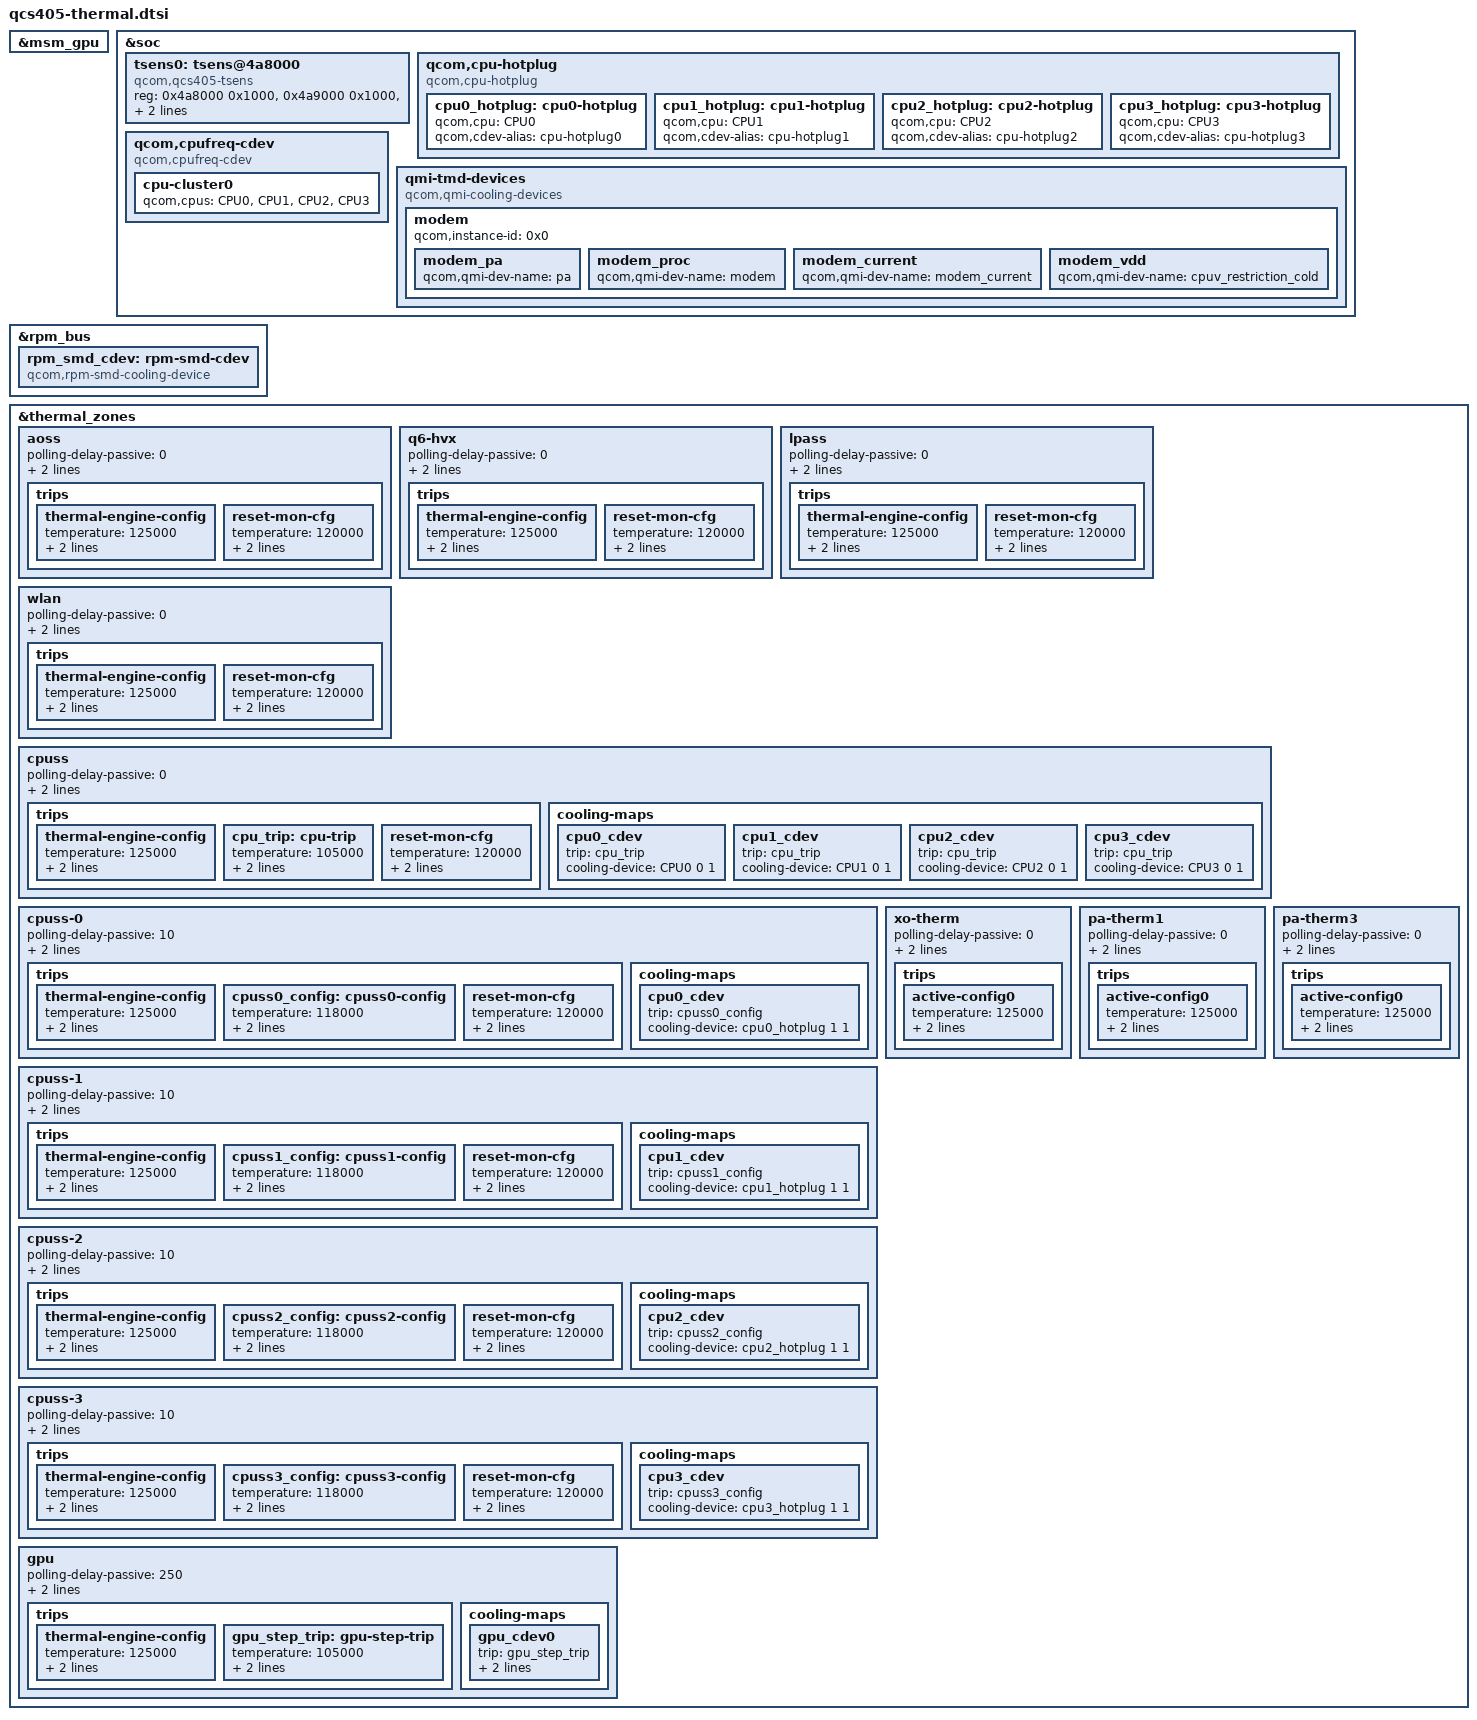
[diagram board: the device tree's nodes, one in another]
#include <dt-bindings/thermal/thermal_qti.h>

&msm_gpu {
    #cooling-cells = <2>;
};

&soc {
	tsens0: tsens@4a8000 {
		compatible = "qcom,qcs405-tsens";
		reg = <0x4a8000 0x1000>,
			<0x4a9000 0x1000>,
			<0xa4000  0x1000>;
		reg-names = "tsens_srot_physical",
			"tsens_tm_physical",
			"tsens_eeprom_physical";
		interrupts = <GIC_SPI 184 IRQ_TYPE_LEVEL_HIGH>;
		interrupt-names = "tsens-upper-lower";
		#thermal-sensor-cells = <1>;
	};

	qcom,cpu-hotplug {
		compatible = "qcom,cpu-hotplug";

		cpu0_hotplug: cpu0-hotplug {
			qcom,cpu = <&CPU0>;
			qcom,cdev-alias = "cpu-hotplug0";
			#cooling-cells = <2>;
		};

		cpu1_hotplug: cpu1-hotplug {
			qcom,cpu = <&CPU1>;
			qcom,cdev-alias = "cpu-hotplug1";
			#cooling-cells = <2>;
		};

		cpu2_hotplug: cpu2-hotplug {
			qcom,cpu = <&CPU2>;
			qcom,cdev-alias = "cpu-hotplug2";
			#cooling-cells = <2>;
		};

		cpu3_hotplug: cpu3-hotplug {
			qcom,cpu = <&CPU3>;
			qcom,cdev-alias = "cpu-hotplug3";
			#cooling-cells = <2>;
		};
	};

	qcom,cpufreq-cdev {
		compatible = "qcom,cpufreq-cdev";
		cpu-cluster0 {
			qcom,cpus = <&CPU0 &CPU1 &CPU2 &CPU3>;
		};
	};

	qmi-tmd-devices {
		compatible = "qcom,qmi-cooling-devices";

		modem {
			qcom,instance-id = <0x0>;

			modem_pa: modem_pa {
				qcom,qmi-dev-name = "pa";
				#cooling-cells = <2>;
			};

			modem_proc: modem_proc {
				qcom,qmi-dev-name = "modem";
				#cooling-cells = <2>;
			};

			modem_current: modem_current {
				qcom,qmi-dev-name = "modem_current";
				#cooling-cells = <2>;
			};

			modem_vdd: modem_vdd {
				qcom,qmi-dev-name = "cpuv_restriction_cold";
				#cooling-cells = <2>;
			};
		};
	};
};

&rpm_bus {
	rpm_smd_cdev: rpm-smd-cdev {
		compatible = "qcom,rpm-smd-cooling-device";
		#cooling-cells = <2>;
	};
};

&thermal_zones {
	aoss {
		polling-delay-passive = <0>;
		polling-delay = <0>;
		thermal-sensors = <&tsens0 0>;
		trips {
			thermal-engine-config {
				temperature = <125000>;
				hysteresis = <1000>;
				type = "passive";
			};

			reset-mon-cfg {
				temperature = <120000>;
				hysteresis = <5000>;
				type = "passive";
			};
		};
	};

	q6-hvx {
		polling-delay-passive = <0>;
		polling-delay = <0>;
		thermal-sensors = <&tsens0 1>;
		trips {
			thermal-engine-config {
				temperature = <125000>;
				hysteresis = <1000>;
				type = "passive";
			};

			reset-mon-cfg {
				temperature = <120000>;
				hysteresis = <5000>;
				type = "passive";
			};
		};
	};

	lpass {
		polling-delay-passive = <0>;
		polling-delay = <0>;
		thermal-sensors = <&tsens0 2>;
		trips {
			thermal-engine-config {
				temperature = <125000>;
				hysteresis = <1000>;
				type = "passive";
			};

			reset-mon-cfg {
				temperature = <120000>;
				hysteresis = <5000>;
				type = "passive";
			};
		};
	};

	wlan {
		polling-delay-passive = <0>;
		polling-delay = <0>;
		thermal-sensors = <&tsens0 3>;
		trips {
			thermal-engine-config {
				temperature = <125000>;
				hysteresis = <1000>;
				type = "passive";
			};

			reset-mon-cfg {
				temperature = <120000>;
				hysteresis = <5000>;
				type = "passive";
			};
		};
	};

	cpuss {
		polling-delay-passive = <0>;
		polling-delay = <0>;
		thermal-sensors = <&tsens0 4>;
		trips {
			thermal-engine-config {
				temperature = <125000>;
				hysteresis = <1000>;
				type = "passive";
			};

			cpu_trip:cpu-trip {
				temperature = <105000>;
				hysteresis = <0>;
				type = "passive";
			};

			reset-mon-cfg {
				temperature = <120000>;
				hysteresis = <5000>;
				type = "passive";
			};
		};

		cooling-maps {
			cpu0_cdev {
				trip = <&cpu_trip>;
				cooling-device = <&CPU0 0 1>;
			};

			cpu1_cdev {
				trip = <&cpu_trip>;
				cooling-device = <&CPU1 0 1>;
			};

			cpu2_cdev {
				trip = <&cpu_trip>;
				cooling-device = <&CPU2 0 1>;
			};

			cpu3_cdev {
				trip = <&cpu_trip>;
				cooling-device = <&CPU3 0 1>;
			};
		};
	};

	cpuss-0 {
		polling-delay-passive = <10>;
		polling-delay = <0>;
		thermal-sensors = <&tsens0 5>;
		trips {
			thermal-engine-config {
				temperature = <125000>;
				hysteresis = <1000>;
				type = "passive";
			};

			cpuss0_config: cpuss0-config {
				temperature = <118000>;
				hysteresis = <10000>;
				type = "passive";
			};

			reset-mon-cfg {
				temperature = <120000>;
				hysteresis = <5000>;
				type = "passive";
			};
		};

		cooling-maps {
			cpu0_cdev {
				trip = <&cpuss0_config>;
				cooling-device = <&cpu0_hotplug 1 1>;
			};
		};
	};

	cpuss-1 {
		polling-delay-passive = <10>;
		polling-delay = <0>;
		thermal-sensors = <&tsens0 6>;
		trips {
			thermal-engine-config {
				temperature = <125000>;
				hysteresis = <1000>;
				type = "passive";
			};

			cpuss1_config: cpuss1-config {
				temperature = <118000>;
				hysteresis = <10000>;
				type = "passive";
			};

			reset-mon-cfg {
				temperature = <120000>;
				hysteresis = <5000>;
				type = "passive";
			};
		};

		cooling-maps {
			cpu1_cdev {
				trip = <&cpuss1_config>;
				cooling-device = <&cpu1_hotplug 1 1>;
			};
		};
	};

	cpuss-2 {
		polling-delay-passive = <10>;
		polling-delay = <0>;
		thermal-sensors = <&tsens0 7>;
		trips {
			thermal-engine-config {
				temperature = <125000>;
				hysteresis = <1000>;
				type = "passive";
			};

			cpuss2_config: cpuss2-config {
				temperature = <118000>;
				hysteresis = <10000>;
				type = "passive";
			};

			reset-mon-cfg {
				temperature = <120000>;
				hysteresis = <5000>;
				type = "passive";
			};
		};

		cooling-maps {
			cpu2_cdev {
				trip = <&cpuss2_config>;
				cooling-device = <&cpu2_hotplug 1 1>;
			};
		};
	};

	cpuss-3 {
		polling-delay-passive = <10>;
		polling-delay = <0>;
		thermal-sensors = <&tsens0 8>;
		trips {
			thermal-engine-config {
				temperature = <125000>;
				hysteresis = <1000>;
				type = "passive";
			};

			cpuss3_config: cpuss3-config {
				temperature = <118000>;
				hysteresis = <10000>;
				type = "passive";
			};

			reset-mon-cfg {
				temperature = <120000>;
				hysteresis = <5000>;
				type = "passive";
			};
		};

		cooling-maps {
			cpu3_cdev {
				trip = <&cpuss3_config>;
				cooling-device = <&cpu3_hotplug 1 1>;
			};
		};
	};

	gpu {
		polling-delay-passive = <250>;
		polling-delay = <0>;
		thermal-sensors = <&tsens0 9>;
		trips {
			thermal-engine-config {
				temperature = <125000>;
				hysteresis = <1000>;
				type = "passive";
			};

			gpu_step_trip: gpu-step-trip {
				temperature = <105000>;
				hysteresis = <0>;
				type = "passive";
			};
		};

		cooling-maps {
			gpu_cdev0 {
				trip = <&gpu_step_trip>;
				cooling-device =
					<&msm_gpu THERMAL_NO_LIMIT
						THERMAL_NO_LIMIT>;
			};
		};
	};

	xo-therm {
		polling-delay-passive = <0>;
		polling-delay = <0>;
		thermal-sensors = <&pms405_adc_tm_iio 0>;

		trips {
			active-config0 {
				temperature = <125000>;
				hysteresis = <1000>;
				type = "passive";
			};
		};
	};

	pa-therm1 {
		polling-delay-passive = <0>;
		polling-delay = <0>;
		thermal-sensors = <&pms405_adc_tm_iio 1>;

		trips {
			active-config0 {
				temperature = <125000>;
				hysteresis = <1000>;
				type = "passive";
			};
		};
	};

	pa-therm3 {
		polling-delay-passive = <0>;
		polling-delay = <0>;
		thermal-sensors = <&pms405_adc_tm_iio 2>;

		trips {
			active-config0 {
				temperature = <125000>;
				hysteresis = <1000>;
				type = "passive";
			};
		};
	};
};
